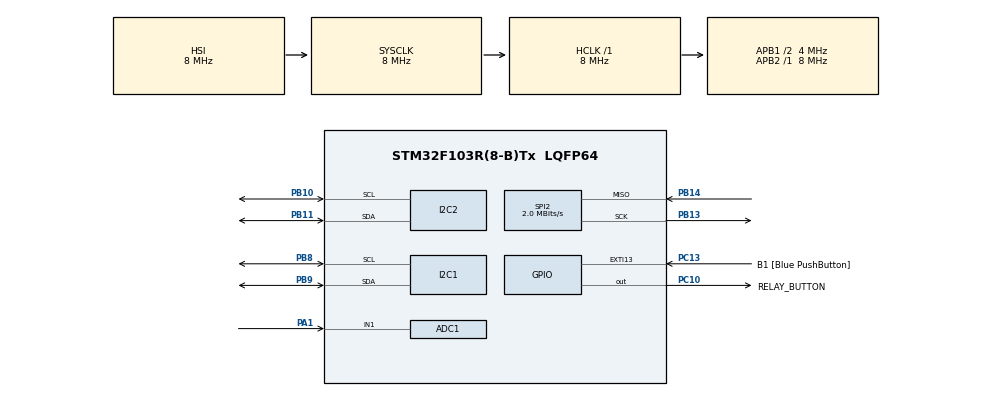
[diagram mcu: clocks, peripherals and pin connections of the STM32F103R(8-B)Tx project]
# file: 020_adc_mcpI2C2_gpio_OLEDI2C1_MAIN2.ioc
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ADC1.Channel-5\#ChannelRegularConversion=ADC_CHANNEL_1
ADC1.NbrOfConversionFlag=1
ADC1.Rank-5\#ChannelRegularConversion=1
ADC1.SamplingTime-5\#ChannelRegularConversion=ADC_SAMPLETIME_1CYCLE_5
ADC1.master=1
I2C1.OwnAddress=0x0
I2C2.OwnAddress=0x0
Mcu.Family=STM32F1
Mcu.Name=STM32F103R(8-B)Tx
Mcu.Package=LQFP64
NVIC.EXTI15_10_IRQn=true\:0\:0\:false\:false\:true\:true\:true\:true
NVIC.PriorityGroup=NVIC_PRIORITYGROUP_4
PA1.Signal=ADCx_IN1
PA13.GPIO_Label=TMS
PA13.Mode=Serial_Wire
PA13.Signal=SYS_JTMS-SWDIO
PA14.GPIO_Label=TCK
PA14.Mode=Serial_Wire
PA14.Signal=SYS_JTCK-SWCLK
PB10.Mode=I2C
PB10.Signal=I2C2_SCL
PB11.Mode=I2C
PB11.Signal=I2C2_SDA
PB13.Mode=RX_Only_Simplex_Unidirect_Master
PB13.Signal=SPI2_SCK
PB14.Mode=RX_Only_Simplex_Unidirect_Master
PB14.Signal=SPI2_MISO
PB3.GPIO_Label=SWO
PB3.Signal=SYS_JTDO-TRACESWO
PB8.Mode=I2C
PB8.Signal=I2C1_SCL
PB9.Mode=I2C
PB9.Signal=I2C1_SDA
PC10.GPIO_Label=RELAY_BUTTON
PC10.GPIO_ModeDefaultOutputPP=GPIO_MODE_OUTPUT_OD
PC10.GPIO_PuPd=GPIO_NOPULL
PC10.Signal=GPIO_Output
PC13-TAMPER-RTC.GPIO_Label=B1 [Blue PushButton]
PC13-TAMPER-RTC.GPIO_PuPd=GPIO_NOPULL
PC13-TAMPER-RTC.Signal=GPXTI13
PC14-OSC32_IN.Mode=LSE-External-Oscillator
PC14-OSC32_IN.Signal=RCC_OSC32_IN
PC15-OSC32_OUT.Mode=LSE-External-Oscillator
PC15-OSC32_OUT.Signal=RCC_OSC32_OUT
PD0-OSC_IN.Mode=HSE-External-Clock-Source
PD0-OSC_IN.Signal=RCC_OSC_IN
PD1-OSC_OUT.Mode=HSE-External-Clock-Source
PD1-OSC_OUT.Signal=RCC_OSC_OUT
ProjectManager.HeapSize=0x200
ProjectManager.StackSize=0x400
ProjectManager.TargetToolchain=STM32CubeIDE
RCC.AHBFreq_Value=8000000
RCC.APB1CLKDivider=RCC_HCLK_DIV2
RCC.APB1Freq_Value=4000000
RCC.APB1TimFreq_Value=8000000
RCC.APB2Freq_Value=8000000
RCC.APB2TimFreq_Value=8000000
RCC.HCLKFreq_Value=8000000
RCC.RTCClockSelection=RCC_RTCCLKSOURCE_LSE
RCC.SYSCLKFreq_VALUE=8000000
RCC.USBFreq_Value=8000000
SH.ADCx_IN1.0=ADC1_IN1,IN1
SPI2.BaudRatePrescaler=SPI_BAUDRATEPRESCALER_2
SPI2.CalculateBaudRate=2.0 MBits/s
SPI2.DataSize=SPI_DATASIZE_16BIT
SPI2.Direction=SPI_DIRECTION_2LINES_RXONLY
SPI2.Mode=SPI_MODE_MASTER
SPI2.VirtualType=VM_MASTER
board=NUCLEO-F103RB

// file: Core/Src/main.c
/* USER CODE BEGIN Header */
/**
  ******************************************************************************
  * @file           : main.c
  * @brief          : Main program body
  ******************************************************************************
  * @attention
  *
  * Copyright (c) 2025 STMicroelectronics.
  * All rights reserved.
  *
  * This software is licensed under terms that can be found in the LICENSE file
  * in the root directory of this software component.
  * If no LICENSE file comes with this software, it is provided AS-IS.
  *
  ******************************************************************************
  */
/* USER CODE END Header */
#include "main.h"

ADC_HandleTypeDef hadc1;

I2C_HandleTypeDef hi2c1;
I2C_HandleTypeDef hi2c2;

SPI_HandleTypeDef hspi2;

void SystemClock_Config(void);
static void MX_GPIO_Init(void);
static void MX_ADC1_Init(void);
static void MX_I2C2_Init(void);
static void MX_I2C1_Init(void);
static void MX_SPI2_Init(void);

/* USER CODE BEGIN 0 */
MCP4725 myMCP4725;

/* USER CODE END 0 */

int main(void)
{

  /* USER CODE BEGIN 1 */
	volatile uint32_t value;
	//char mytext[] = "hello oled";
	//char retval;

  /* USER CODE END 1 */

  /* MCU Configuration--------------------------------------------------------*/

  /* Reset of all peripherals, Initializes the Flash interface and the Systick. */
  HAL_Init();

  /* Configure the system clock */
  SystemClock_Config();

  /* Initialize all configured peripherals */
  MX_GPIO_Init();
  MX_ADC1_Init();
  MX_I2C2_Init();
  MX_I2C1_Init();
  MX_SPI2_Init();
  /* USER CODE BEGIN 2 */
  HAL_ADC_Start (&hadc1);

  printf("hello world\n");

// OLED INIT
  ssd1306_Init();

  // Second, initilaize the MCP4725 object:
  	myMCP4725 = MCP4725_init(&hi2c2, MCP4725A0_ADDR_A01, 5.0);

  	// Check the connection:
  	if(MCP4725_isConnected(&myMCP4725)){

  		// Print that the DAC is coonected
  		printf("dac is connected -- \n");

  	}
  	else{

  		// Print that the DAC is NOT coonected
  		printf("not connected\n");

  	}

  	HAL_Delay(5000);
  	printf("delay 5sec after dac is connected \n");

  /* USER CODE END 2 */

  /* Infinite loop */
  /* USER CODE BEGIN WHILE */
    while (1)
    {

    	/////////////  while begin

    	  HAL_ADC_PollForConversion (&hadc1, 100);
    	  value = HAL_ADC_GetValue (&hadc1);
    	  // printf("value = %ld\n",value);
    	  float voltage = (value * 5.0f) / 4096.0f;

    	  // Print voltage
    		         // printf("ADC Value: %lu, Voltage: %.2f V\n", value, voltage);
    	  //printf(" adc value == %ld  ---  Voltage: %.2f V\n",value, voltage);
    	  printf(" %ld     %.2f V\n",value, voltage);
    	  //MCP4725_setVoltage(&myMCP4725,voltage, MCP4725_FAST_MODE, MCP4725_POWER_DOWN_OFF);
    	  HAL_Delay(4000);
    	  ////////////////////////////////////

      	  if(voltage <= 1.0){
      		  MCP4725_setVoltage(&myMCP4725,1.0f, MCP4725_FAST_MODE, MCP4725_POWER_DOWN_OFF);
      		  printf("if voltage <=1 --> mcp_setvoltgae(1)\n");
      	  }else if(voltage >1.0 && voltage <=2.0){
      		  MCP4725_setVoltage(&myMCP4725,2.0f, MCP4725_FAST_MODE, MCP4725_POWER_DOWN_OFF);
      		 		  printf("if voltage <=2 --> mcp_setvoltgae(2)\n");

      	  }else if(voltage >2.0 && voltage <=3.0){
      		  MCP4725_setVoltage(&myMCP4725,3.0f, MCP4725_FAST_MODE, MCP4725_POWER_DOWN_OFF);
      		 		  printf("if voltage <=3 --> mcp_setvoltgae(3)\n");

      	  }else if(voltage >3.0 && voltage <=4.0){
      		  MCP4725_setVoltage(&myMCP4725,4.0f, MCP4725_FAST_MODE, MCP4725_POWER_DOWN_OFF);
      		 		  printf("if voltage <=4 --> mcp_setvoltgae(4)\n");

      	  }else if(voltage >4.0 && voltage <=5.0){
      		  MCP4725_setVoltage(&myMCP4725,5.0f, MCP4725_FAST_MODE, MCP4725_POWER_DOWN_OFF);
      		 		  printf("if voltage <=5 --> mcp_setvoltgae(5)\n");

      	  }

      	  ///////////////////////////////////////////////////////////////////////////////
      	  //
      	  //               GPIO RELAY CONTROL
      	  //                -----------------
      	  //      OUTPUT MODE -- LOW
      	  //               OPEN DRAIN EXTERNAL PULL UP CONFIG  (NO PUSH PULL FROM INSIDE OPEN DRAIN)
      	  //       PC10

      	   /*
      	     if(temperature > 60 && temperature<90){

    	        	HAL_GPIO_WritePin(GPIOC, GPIO_PIN_10, GPIO_PIN_SET );
    	        	HAL_GPIO_TogglePin(GPIOC, GPIO_PIN_10);
    	        }
    	        else{
    	         	HAL_GPIO_WritePin(GPIOC, GPIO_PIN_10, GPIO_PIN_RESET );
    	        }

      	    */
       	 ///////////////////////////////////////////////////////////////////////////////

       	  ///////////////////////////////////
       	  /*
       	  //MCP4725_setVoltage(&myMCP4725,5.0f, MCP4725_FAST_MODE, MCP4725_POWER_DOWN_OFF);
       	  MCP4725_setValue(&myMCP4725, 500, MCP4725_FAST_MODE, MCP4725_POWER_DOWN_OFF);
       	  printf("dac_value= 500\n");
       	  HAL_Delay(10000);
       	  */

      	  ///////////////////////////////////////////////////////////////////////
      	  //
      	  //       i2c1  OLED
      	  //
      	  //
/*
   // ssd1306_Fill(White);
  //printf("ssd1306 fill white \n");

  //ssd1306_UpdateScreen();

  ssd1306_SetCursor(5,5);
  retval = ssd1306_WriteString(mytext,Font_7x10,White);
  ssd1306_UpdateScreen();

 */

      	  /////////// while end

    }
  /* USER CODE END 3 */
}

void SystemClock_Config(void)
{
  RCC_OscInitTypeDef RCC_OscInitStruct = {0};
  RCC_ClkInitTypeDef RCC_ClkInitStruct = {0};
  RCC_PeriphCLKInitTypeDef PeriphClkInit = {0};

  /** Initializes the RCC Oscillators according to the specified parameters
  * in the RCC_OscInitTypeDef structure.
  */
  RCC_OscInitStruct.OscillatorType = RCC_OSCILLATORTYPE_HSI;
  RCC_OscInitStruct.HSIState = RCC_HSI_ON;
  RCC_OscInitStruct.HSICalibrationValue = RCC_HSICALIBRATION_DEFAULT;
  RCC_OscInitStruct.PLL.PLLState = RCC_PLL_NONE;
  if (HAL_RCC_OscConfig(&RCC_OscInitStruct) != HAL_OK)
  {
    Error_Handler();
  }

  /** Initializes the CPU, AHB and APB buses clocks
  */
  RCC_ClkInitStruct.ClockType = RCC_CLOCKTYPE_HCLK|RCC_CLOCKTYPE_SYSCLK
                              |RCC_CLOCKTYPE_PCLK1|RCC_CLOCKTYPE_PCLK2;
  RCC_ClkInitStruct.SYSCLKSource = RCC_SYSCLKSOURCE_HSI;
  RCC_ClkInitStruct.AHBCLKDivider = RCC_SYSCLK_DIV1;
  RCC_ClkInitStruct.APB1CLKDivider = RCC_HCLK_DIV2;
  RCC_ClkInitStruct.APB2CLKDivider = RCC_HCLK_DIV1;

  if (HAL_RCC_ClockConfig(&RCC_ClkInitStruct, FLASH_LATENCY_0) != HAL_OK)
  {
    Error_Handler();
  }
  PeriphClkInit.PeriphClockSelection = RCC_PERIPHCLK_ADC;
  PeriphClkInit.AdcClockSelection = RCC_ADCPCLK2_DIV2;
  if (HAL_RCCEx_PeriphCLKConfig(&PeriphClkInit) != HAL_OK)
  {
    Error_Handler();
  }
}

static void MX_ADC1_Init(void)
{

  ADC_ChannelConfTypeDef sConfig = {0};

  /** Common config
  */
  hadc1.Instance = ADC1;
  hadc1.Init.ScanConvMode = ADC_SCAN_ENABLE;
  hadc1.Init.ContinuousConvMode = ENABLE;
  hadc1.Init.DiscontinuousConvMode = DISABLE;
  hadc1.Init.ExternalTrigConv = ADC_SOFTWARE_START;
  hadc1.Init.DataAlign = ADC_DATAALIGN_RIGHT;
  hadc1.Init.NbrOfConversion = 1;
  if (HAL_ADC_Init(&hadc1) != HAL_OK)
  {
    Error_Handler();
  }

  /** Configure Regular Channel
  */
  sConfig.Channel = ADC_CHANNEL_1;
  sConfig.Rank = ADC_REGULAR_RANK_1;
  sConfig.SamplingTime = ADC_SAMPLETIME_1CYCLE_5;
  if (HAL_ADC_ConfigChannel(&hadc1, &sConfig) != HAL_OK)
  {
    Error_Handler();
  }

}

static void MX_I2C1_Init(void)
{

  hi2c1.Instance = I2C1;
  hi2c1.Init.ClockSpeed = 100000;
  hi2c1.Init.DutyCycle = I2C_DUTYCYCLE_2;
  hi2c1.Init.OwnAddress1 = 0;
  hi2c1.Init.AddressingMode = I2C_ADDRESSINGMODE_7BIT;
  hi2c1.Init.DualAddressMode = I2C_DUALADDRESS_DISABLE;
  hi2c1.Init.OwnAddress2 = 0;
  hi2c1.Init.GeneralCallMode = I2C_GENERALCALL_DISABLE;
  hi2c1.Init.NoStretchMode = I2C_NOSTRETCH_DISABLE;
  if (HAL_I2C_Init(&hi2c1) != HAL_OK)
  {
    Error_Handler();
  }

}

static void MX_I2C2_Init(void)
{

  hi2c2.Instance = I2C2;
  hi2c2.Init.ClockSpeed = 100000;
  hi2c2.Init.DutyCycle = I2C_DUTYCYCLE_2;
  hi2c2.Init.OwnAddress1 = 0;
  hi2c2.Init.AddressingMode = I2C_ADDRESSINGMODE_7BIT;
  hi2c2.Init.DualAddressMode = I2C_DUALADDRESS_DISABLE;
  hi2c2.Init.OwnAddress2 = 0;
  hi2c2.Init.GeneralCallMode = I2C_GENERALCALL_DISABLE;
  hi2c2.Init.NoStretchMode = I2C_NOSTRETCH_DISABLE;
  if (HAL_I2C_Init(&hi2c2) != HAL_OK)
  {
    Error_Handler();
  }

}

static void MX_SPI2_Init(void)
{

  /* SPI2 parameter configuration*/
  hspi2.Instance = SPI2;
  hspi2.Init.Mode = SPI_MODE_MASTER;
  hspi2.Init.Direction = SPI_DIRECTION_2LINES_RXONLY;
  hspi2.Init.DataSize = SPI_DATASIZE_16BIT;
  hspi2.Init.CLKPolarity = SPI_POLARITY_LOW;
  hspi2.Init.CLKPhase = SPI_PHASE_1EDGE;
  hspi2.Init.NSS = SPI_NSS_SOFT;
  hspi2.Init.BaudRatePrescaler = SPI_BAUDRATEPRESCALER_2;
  hspi2.Init.FirstBit = SPI_FIRSTBIT_MSB;
  hspi2.Init.TIMode = SPI_TIMODE_DISABLE;
  hspi2.Init.CRCCalculation = SPI_CRCCALCULATION_DISABLE;
  hspi2.Init.CRCPolynomial = 10;
  if (HAL_SPI_Init(&hspi2) != HAL_OK)
  {
    Error_Handler();
  }

}

static void MX_GPIO_Init(void)
{
  GPIO_InitTypeDef GPIO_InitStruct = {0};

  /* GPIO Ports Clock Enable */
  __HAL_RCC_GPIOC_CLK_ENABLE();
  __HAL_RCC_GPIOD_CLK_ENABLE();
  __HAL_RCC_GPIOA_CLK_ENABLE();
  __HAL_RCC_GPIOB_CLK_ENABLE();

  /*Configure GPIO pin Output Level */
  HAL_GPIO_WritePin(RELAY_BUTTON_GPIO_Port, RELAY_BUTTON_Pin, GPIO_PIN_RESET);

  /*Configure GPIO pin : B1_Pin */
  GPIO_InitStruct.Pin = B1_Pin;
  GPIO_InitStruct.Mode = GPIO_MODE_IT_RISING;
  GPIO_InitStruct.Pull = GPIO_NOPULL;
  HAL_GPIO_Init(B1_GPIO_Port, &GPIO_InitStruct);

  /*Configure GPIO pin : RELAY_BUTTON_Pin */
  GPIO_InitStruct.Pin = RELAY_BUTTON_Pin;
  GPIO_InitStruct.Mode = GPIO_MODE_OUTPUT_OD;
  GPIO_InitStruct.Pull = GPIO_NOPULL;
  GPIO_InitStruct.Speed = GPIO_SPEED_FREQ_LOW;
  HAL_GPIO_Init(RELAY_BUTTON_GPIO_Port, &GPIO_InitStruct);

  /* EXTI interrupt init*/
  HAL_NVIC_SetPriority(EXTI15_10_IRQn, 0, 0);
  HAL_NVIC_EnableIRQ(EXTI15_10_IRQn);

}

void Error_Handler(void)
{
  __disable_irq();
  while (1)
  {
  }
}
